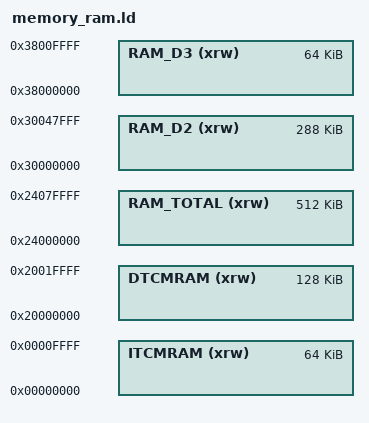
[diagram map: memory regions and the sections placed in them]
MEMORY
{
    ITCMRAM (xrw)  : ORIGIN = 0x00000000, LENGTH = 64K
    DTCMRAM (xrw)  : ORIGIN = 0x20000000, LENGTH = 128K
    RAM_TOTAL (xrw)      : ORIGIN = 0x24000000, LENGTH = 512K
    RAM_D2 (xrw)   : ORIGIN = 0x30000000, LENGTH = 288K
    RAM_D3 (xrw)   : ORIGIN = 0x38000000, LENGTH = 64K
}

MEMORY
{
    RAM_ACTIVE(rwx): ORIGIN = ORIGIN(RAM_TOTAL)                    , LENGTH = LENGTH(RAM_TOTAL) - 4
    SKIP_CODES (rw): ORIGIN = ORIGIN(RAM_TOTAL) + LENGTH(RAM_TOTAL), LENGTH = 4
}
